# CTRL_MMR0_CFG0 register map
Vendor: Texas Instruments
Registers are 32-bit, read-write, reset 0x0 unless marked. A register's access mark holds for its fields unless they carry their own. Offsets are as the file gives them; [hi:lo] are bit positions; {n}, {i} and the like mark numbered series.

## CTRL_MMR0_CFG0 (part 7 of 9)
0xC290 CFG0_DSP0_LBIST_SIG ro — Contains expected MISR output value
  [31:0] DSP0_LBIST_SIG_MISR_SIG — MISR signature
0xC294 CFG0_DSP1_LBIST_SIG ro — Contains expected MISR output value
  [31:0] DSP1_LBIST_SIG_MISR_SIG — MISR signature
0xC2A0 CFG0_MPU0_LBIST_SIG ro — Contains expected MISR output value
  [31:0] MPU0_LBIST_SIG_MISR_SIG — MISR signature
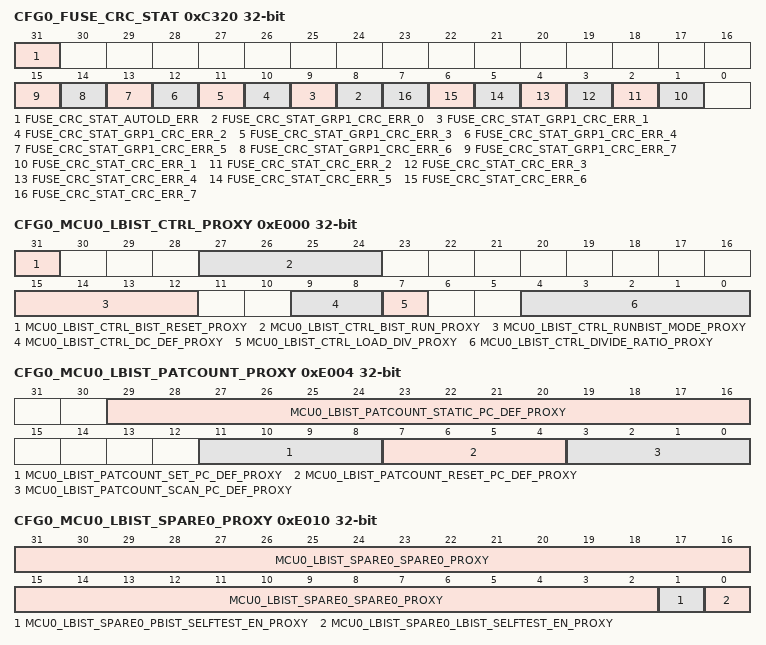
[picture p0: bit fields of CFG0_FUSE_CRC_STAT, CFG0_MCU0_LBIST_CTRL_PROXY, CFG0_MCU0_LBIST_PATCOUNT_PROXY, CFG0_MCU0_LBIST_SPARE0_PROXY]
0xC320 CFG0_FUSE_CRC_STAT ro — Indicates status of fuse chain CRC
  [31] FUSE_CRC_STAT_AUTOLD_ERR — Indicates eFuse autoload or programmation error on any chain
  [n+8] FUSE_CRC_STAT_GRP1_CRC_ERR_{n} (n=0..7) — Indicates eFuse CRC error on group1 chain {n}
  [n] FUSE_CRC_STAT_CRC_ERR_{n} (n=1..7) — Indicates eFuse CRC error on chain {n}
{0xD100+4i} CFG0_CLAIMREG_P3_R{i}_READONLY ro (i=0..13)
  [31:0] CLAIMREG_P3_R{i}_READONLY — Claim bits for Partition 3
0xE000 CFG0_MCU0_LBIST_CTRL_PROXY — Configures and enables LBIST operation
  [31] MCU0_LBIST_CTRL_BIST_RESET_PROXY — Reset LBIST macro
  [27:24] MCU0_LBIST_CTRL_BIST_RUN_PROXY — Starts LBIST if all bits are 1
  [15:12] MCU0_LBIST_CTRL_RUNBIST_MODE_PROXY — Runbist mode enable if all bits are 1
  [9:8] MCU0_LBIST_CTRL_DC_DEF_PROXY — Clock delay after scan_enable switching
  [7] MCU0_LBIST_CTRL_LOAD_DIV_PROXY — Loads LBIST clock divide ratio on transition from 0 to 1
  [4:0] MCU0_LBIST_CTRL_DIVIDE_RATIO_PROXY — LBIST clock divide ratio
0xE004 CFG0_MCU0_LBIST_PATCOUNT_PROXY — Specifies the number of LBIST patterns to run
  [29:16] MCU0_LBIST_PATCOUNT_STATIC_PC_DEF_PROXY — Number of stuck-at patterns to run
  [11:8] MCU0_LBIST_PATCOUNT_SET_PC_DEF_PROXY — Number of set patterns to run
  [7:4] MCU0_LBIST_PATCOUNT_RESET_PC_DEF_PROXY — Number of reset patterns to run
  [3:0] MCU0_LBIST_PATCOUNT_SCAN_PC_DEF_PROXY — Number of chain test patterns to run
0xE008 CFG0_MCU0_LBIST_SEED0_PROXY — Specifies the 32 LSBs of the PRPG seed
  [31:0] MCU0_LBIST_SEED0_PRPG_DEF_PROXY — Initial seed for PRPG (bits 31:0)
0xE00C CFG0_MCU0_LBIST_SEED1_PROXY — Specifies the 21 MSBs of the PRPG seed
  [20:0] MCU0_LBIST_SEED1_PRPG_DEF_PROXY — Initial seed for PRPG (bits 52:32)
0xE010 CFG0_MCU0_LBIST_SPARE0_PROXY — Spare LBIST control bits
  [31:2] MCU0_LBIST_SPARE0_SPARE0_PROXY — LBIST spare bits
  [1] MCU0_LBIST_SPARE0_PBIST_SELFTEST_EN_PROXY — PBIST isolation control
  [0] MCU0_LBIST_SPARE0_LBIST_SELFTEST_EN_PROXY — LBIST isolation control
0xE014 CFG0_MCU0_LBIST_SPARE1_PROXY — Spare LBIST control bits
  [31:0] MCU0_LBIST_SPARE1_SPARE1_PROXY — LBIST spare bits
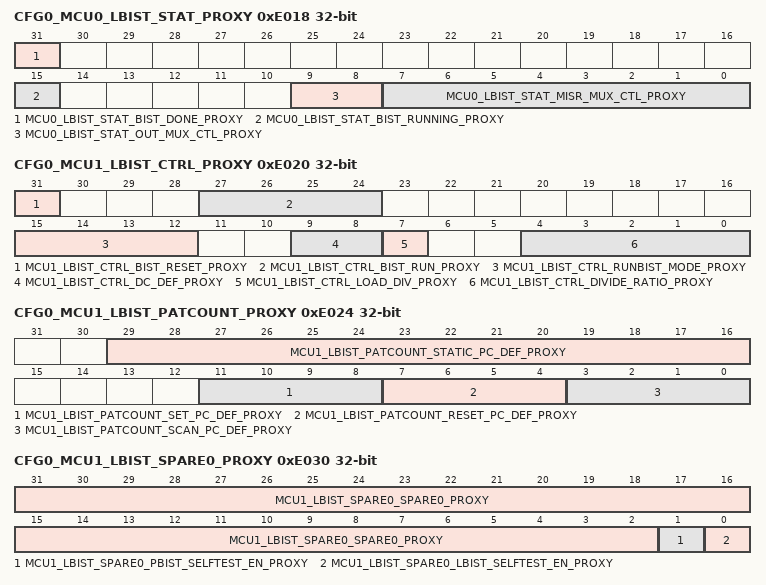
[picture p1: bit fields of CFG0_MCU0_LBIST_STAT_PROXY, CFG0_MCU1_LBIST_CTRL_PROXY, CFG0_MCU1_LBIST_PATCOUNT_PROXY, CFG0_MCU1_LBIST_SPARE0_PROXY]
0xE018 CFG0_MCU0_LBIST_STAT_PROXY access per field — Indicates LBIST status and provides MISR selection control
  [31] MCU0_LBIST_STAT_BIST_DONE_PROXY ro — LBIST is done
  [15] MCU0_LBIST_STAT_BIST_RUNNING_PROXY ro — LBIST is running
  [9:8] MCU0_LBIST_STAT_OUT_MUX_CTL_PROXY rw — Selects source of LBIST output 00 - LBIST IP PID value 01 - LBIST CTRL ID value 1x - MISR value
  [7:0] MCU0_LBIST_STAT_MISR_MUX_CTL_PROXY rw — Selects block of 32 MISR bits to read. A value of 0 selects a compacted 32-bit version of the full MISR. A value of 1-32 select a 32-bit segment of the MISR.
0xE01C CFG0_MCU0_LBIST_MISR_PROXY ro — Contains LBIST MISR output value
  [31:0] MCU0_LBIST_MISR_MISR_RESULT_PROXY — 32-bits of MISR value selected by misr_mux_ctl
0xE020 CFG0_MCU1_LBIST_CTRL_PROXY — Configures and enables LBIST operation
  [31] MCU1_LBIST_CTRL_BIST_RESET_PROXY — Reset LBIST macro
  [27:24] MCU1_LBIST_CTRL_BIST_RUN_PROXY — Starts LBIST if all bits are 1
  [15:12] MCU1_LBIST_CTRL_RUNBIST_MODE_PROXY — Runbist mode enable if all bits are 1
  [9:8] MCU1_LBIST_CTRL_DC_DEF_PROXY — Clock delay after scan_enable switching
  [7] MCU1_LBIST_CTRL_LOAD_DIV_PROXY — Loads LBIST clock divide ratio on transition from 0 to 1
  [4:0] MCU1_LBIST_CTRL_DIVIDE_RATIO_PROXY — LBIST clock divide ratio
0xE024 CFG0_MCU1_LBIST_PATCOUNT_PROXY — Specifies the number of LBIST patterns to run
  [29:16] MCU1_LBIST_PATCOUNT_STATIC_PC_DEF_PROXY — Number of stuck-at patterns to run
  [11:8] MCU1_LBIST_PATCOUNT_SET_PC_DEF_PROXY — Number of set patterns to run
  [7:4] MCU1_LBIST_PATCOUNT_RESET_PC_DEF_PROXY — Number of reset patterns to run
  [3:0] MCU1_LBIST_PATCOUNT_SCAN_PC_DEF_PROXY — Number of chain test patterns to run
0xE028 CFG0_MCU1_LBIST_SEED0_PROXY — Specifies the 32 LSBs of the PRPG seed
  [31:0] MCU1_LBIST_SEED0_PRPG_DEF_PROXY — Initial seed for PRPG (bits 31:0)
0xE02C CFG0_MCU1_LBIST_SEED1_PROXY — Specifies the 21 MSBs of the PRPG seed
  [20:0] MCU1_LBIST_SEED1_PRPG_DEF_PROXY — Initial seed for PRPG (bits 52:32)
0xE030 CFG0_MCU1_LBIST_SPARE0_PROXY — Spare LBIST control bits
  [31:2] MCU1_LBIST_SPARE0_SPARE0_PROXY — LBIST spare bits
  [1] MCU1_LBIST_SPARE0_PBIST_SELFTEST_EN_PROXY — PBIST isolation control
  [0] MCU1_LBIST_SPARE0_LBIST_SELFTEST_EN_PROXY — LBIST isolation control
0xE034 CFG0_MCU1_LBIST_SPARE1_PROXY — Spare LBIST control bits
  [31:0] MCU1_LBIST_SPARE1_SPARE1_PROXY — LBIST spare bits
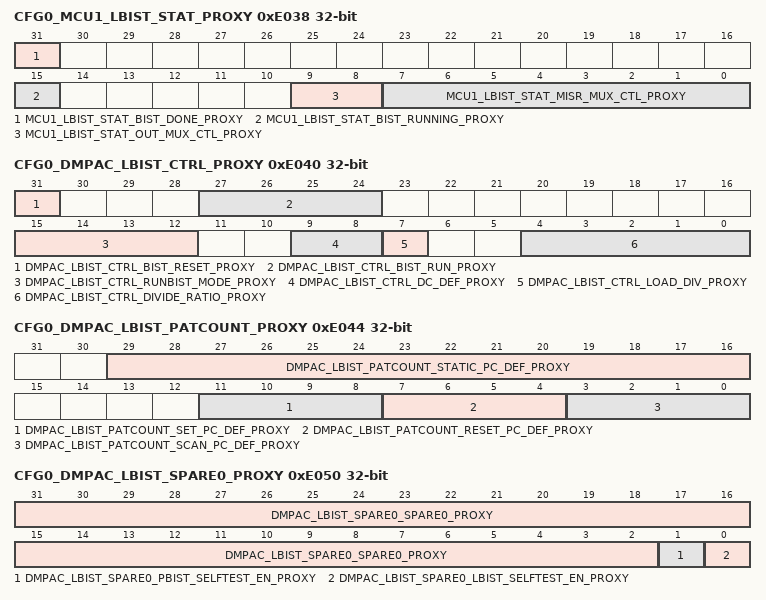
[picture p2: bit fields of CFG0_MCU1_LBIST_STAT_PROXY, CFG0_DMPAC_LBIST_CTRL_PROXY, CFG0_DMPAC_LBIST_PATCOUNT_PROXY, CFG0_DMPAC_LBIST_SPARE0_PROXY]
0xE038 CFG0_MCU1_LBIST_STAT_PROXY access per field — Indicates LBIST status and provides MISR selection control
  [31] MCU1_LBIST_STAT_BIST_DONE_PROXY ro — LBIST is done
  [15] MCU1_LBIST_STAT_BIST_RUNNING_PROXY ro — LBIST is running
  [9:8] MCU1_LBIST_STAT_OUT_MUX_CTL_PROXY rw — Selects source of LBIST output 00 - LBIST IP PID value 01 - LBIST CTRL ID value 1x - MISR value
  [7:0] MCU1_LBIST_STAT_MISR_MUX_CTL_PROXY rw — Selects block of 32 MISR bits to read. A value of 0 selects a compacted 32-bit version of the full MISR. A value of 1-32 select a 32-bit segment of the MISR.
0xE03C CFG0_MCU1_LBIST_MISR_PROXY ro — Contains LBIST MISR output value
  [31:0] MCU1_LBIST_MISR_MISR_RESULT_PROXY — 32-bits of MISR value selected by misr_mux_ctl
0xE040 CFG0_DMPAC_LBIST_CTRL_PROXY — Configures and enables LBIST operation
  [31] DMPAC_LBIST_CTRL_BIST_RESET_PROXY — Reset LBIST macro
  [27:24] DMPAC_LBIST_CTRL_BIST_RUN_PROXY — Starts LBIST if all bits are 1
  [15:12] DMPAC_LBIST_CTRL_RUNBIST_MODE_PROXY — Runbist mode enable if all bits are 1
  [9:8] DMPAC_LBIST_CTRL_DC_DEF_PROXY — Clock delay after scan_enable switching
  [7] DMPAC_LBIST_CTRL_LOAD_DIV_PROXY — Loads LBIST clock divide ratio on transition from 0 to 1
  [4:0] DMPAC_LBIST_CTRL_DIVIDE_RATIO_PROXY — LBIST clock divide ratio
0xE044 CFG0_DMPAC_LBIST_PATCOUNT_PROXY — Specifies the number of LBIST patterns to run
  [29:16] DMPAC_LBIST_PATCOUNT_STATIC_PC_DEF_PROXY — Number of stuck-at patterns to run
  [11:8] DMPAC_LBIST_PATCOUNT_SET_PC_DEF_PROXY — Number of set patterns to run
  [7:4] DMPAC_LBIST_PATCOUNT_RESET_PC_DEF_PROXY — Number of reset patterns to run
  [3:0] DMPAC_LBIST_PATCOUNT_SCAN_PC_DEF_PROXY — Number of chain test patterns to run
0xE048 CFG0_DMPAC_LBIST_SEED0_PROXY — Specifies the 32 LSBs of the PRPG seed
  [31:0] DMPAC_LBIST_SEED0_PRPG_DEF_PROXY — Initial seed for PRPG (bits 31:0)
0xE04C CFG0_DMPAC_LBIST_SEED1_PROXY — Specifies the 21 MSBs of the PRPG seed
  [20:0] DMPAC_LBIST_SEED1_PRPG_DEF_PROXY — Initial seed for PRPG (bits 52:32)
0xE050 CFG0_DMPAC_LBIST_SPARE0_PROXY — Spare LBIST control bits
  [31:2] DMPAC_LBIST_SPARE0_SPARE0_PROXY — LBIST spare bits
  [1] DMPAC_LBIST_SPARE0_PBIST_SELFTEST_EN_PROXY — PBIST isolation control
  [0] DMPAC_LBIST_SPARE0_LBIST_SELFTEST_EN_PROXY — LBIST isolation control
0xE054 CFG0_DMPAC_LBIST_SPARE1_PROXY — Spare LBIST control bits
  [31:0] DMPAC_LBIST_SPARE1_SPARE1_PROXY — LBIST spare bits
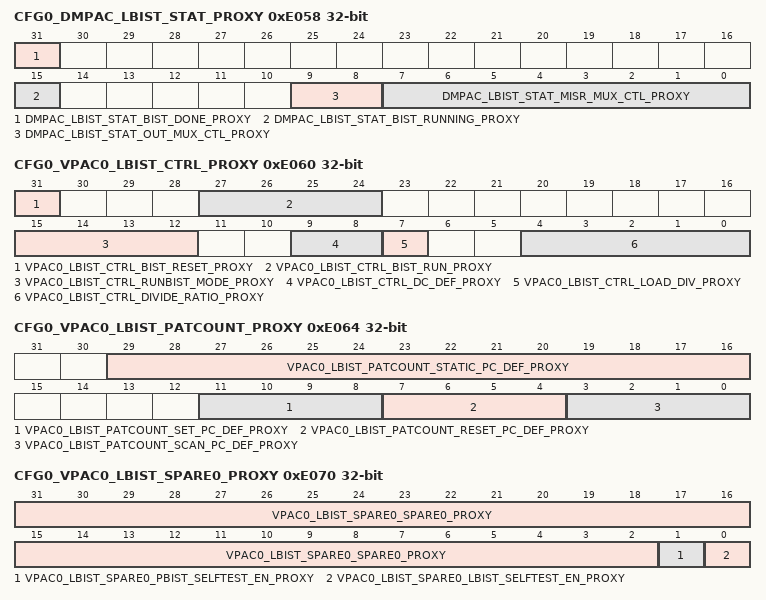
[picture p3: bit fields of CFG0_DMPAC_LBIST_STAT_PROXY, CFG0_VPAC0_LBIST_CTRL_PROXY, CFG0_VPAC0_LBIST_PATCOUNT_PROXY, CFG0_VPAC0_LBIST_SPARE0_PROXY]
0xE058 CFG0_DMPAC_LBIST_STAT_PROXY access per field — Indicates LBIST status and provides MISR selection control
  [31] DMPAC_LBIST_STAT_BIST_DONE_PROXY ro — LBIST is done
  [15] DMPAC_LBIST_STAT_BIST_RUNNING_PROXY ro — LBIST is running
  [9:8] DMPAC_LBIST_STAT_OUT_MUX_CTL_PROXY rw — Selects source of LBIST output 00 - LBIST IP PID value 01 - LBIST CTRL ID value 1x - MISR value
  [7:0] DMPAC_LBIST_STAT_MISR_MUX_CTL_PROXY rw — Selects block of 32 MISR bits to read. A value of 0 selects a compacted 32-bit version of the full MISR. A value of 1-32 select a 32-bit segment of the MISR.
0xE05C CFG0_DMPAC_LBIST_MISR_PROXY ro — Contains LBIST MISR output value
  [31:0] DMPAC_LBIST_MISR_MISR_RESULT_PROXY — 32-bits of MISR value selected by misr_mux_ctl
0xE060 CFG0_VPAC0_LBIST_CTRL_PROXY — Configures and enables LBIST operation
  [31] VPAC0_LBIST_CTRL_BIST_RESET_PROXY — Reset LBIST macro
  [27:24] VPAC0_LBIST_CTRL_BIST_RUN_PROXY — Starts LBIST if all bits are 1
  [15:12] VPAC0_LBIST_CTRL_RUNBIST_MODE_PROXY — Runbist mode enable if all bits are 1
  [9:8] VPAC0_LBIST_CTRL_DC_DEF_PROXY — Clock delay after scan_enable switching
  [7] VPAC0_LBIST_CTRL_LOAD_DIV_PROXY — Loads LBIST clock divide ratio on transition from 0 to 1
  [4:0] VPAC0_LBIST_CTRL_DIVIDE_RATIO_PROXY — LBIST clock divide ratio
0xE064 CFG0_VPAC0_LBIST_PATCOUNT_PROXY — Specifies the number of LBIST patterns to run
  [29:16] VPAC0_LBIST_PATCOUNT_STATIC_PC_DEF_PROXY — Number of stuck-at patterns to run
  [11:8] VPAC0_LBIST_PATCOUNT_SET_PC_DEF_PROXY — Number of set patterns to run
  [7:4] VPAC0_LBIST_PATCOUNT_RESET_PC_DEF_PROXY — Number of reset patterns to run
  [3:0] VPAC0_LBIST_PATCOUNT_SCAN_PC_DEF_PROXY — Number of chain test patterns to run
0xE068 CFG0_VPAC0_LBIST_SEED0_PROXY — Specifies the 32 LSBs of the PRPG seed
  [31:0] VPAC0_LBIST_SEED0_PRPG_DEF_PROXY — Initial seed for PRPG (bits 31:0)
0xE06C CFG0_VPAC0_LBIST_SEED1_PROXY — Specifies the 21 MSBs of the PRPG seed
  [20:0] VPAC0_LBIST_SEED1_PRPG_DEF_PROXY — Initial seed for PRPG (bits 52:32)
0xE070 CFG0_VPAC0_LBIST_SPARE0_PROXY — Spare LBIST control bits
  [31:2] VPAC0_LBIST_SPARE0_SPARE0_PROXY — LBIST spare bits
  [1] VPAC0_LBIST_SPARE0_PBIST_SELFTEST_EN_PROXY — PBIST isolation control
  [0] VPAC0_LBIST_SPARE0_LBIST_SELFTEST_EN_PROXY — LBIST isolation control
0xE074 CFG0_VPAC0_LBIST_SPARE1_PROXY — Spare LBIST control bits
  [31:0] VPAC0_LBIST_SPARE1_SPARE1_PROXY — LBIST spare bits
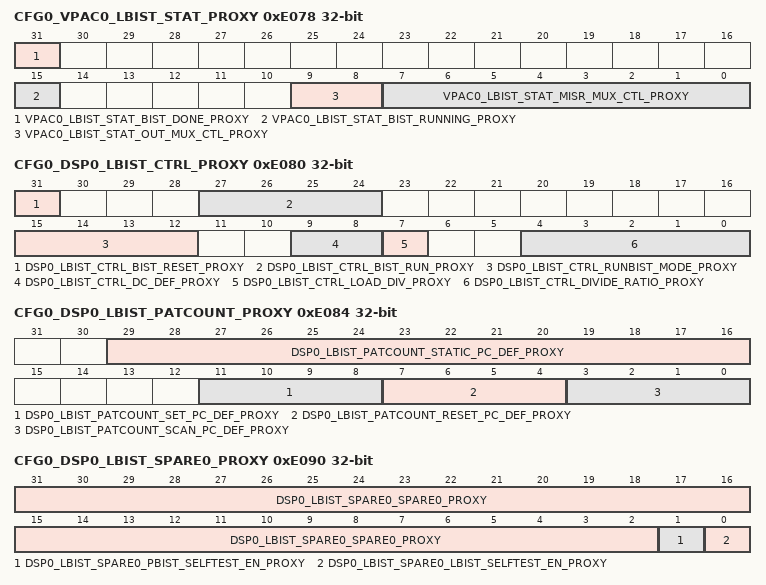
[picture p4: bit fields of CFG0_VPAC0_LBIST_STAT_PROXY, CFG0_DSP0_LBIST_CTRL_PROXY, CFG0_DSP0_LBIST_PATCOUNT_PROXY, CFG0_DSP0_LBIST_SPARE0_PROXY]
0xE078 CFG0_VPAC0_LBIST_STAT_PROXY access per field — Indicates LBIST status and provides MISR selection control
  [31] VPAC0_LBIST_STAT_BIST_DONE_PROXY ro — LBIST is done
  [15] VPAC0_LBIST_STAT_BIST_RUNNING_PROXY ro — LBIST is running
  [9:8] VPAC0_LBIST_STAT_OUT_MUX_CTL_PROXY rw — Selects source of LBIST output 00 - LBIST IP PID value 01 - LBIST CTRL ID value 1x - MISR value
  [7:0] VPAC0_LBIST_STAT_MISR_MUX_CTL_PROXY rw — Selects block of 32 MISR bits to read. A value of 0 selects a compacted 32-bit version of the full MISR. A value of 1-32 select a 32-bit segment of the MISR.
0xE07C CFG0_VPAC0_LBIST_MISR_PROXY ro — Contains LBIST MISR output value
  [31:0] VPAC0_LBIST_MISR_MISR_RESULT_PROXY — 32-bits of MISR value selected by misr_mux_ctl
0xE080 CFG0_DSP0_LBIST_CTRL_PROXY — Configures and enables LBIST operation
  [31] DSP0_LBIST_CTRL_BIST_RESET_PROXY — Reset LBIST macro
  [27:24] DSP0_LBIST_CTRL_BIST_RUN_PROXY — Starts LBIST if all bits are 1
  [15:12] DSP0_LBIST_CTRL_RUNBIST_MODE_PROXY — Runbist mode enable if all bits are 1
  [9:8] DSP0_LBIST_CTRL_DC_DEF_PROXY — Clock delay after scan_enable switching
  [7] DSP0_LBIST_CTRL_LOAD_DIV_PROXY — Loads LBIST clock divide ratio on transition from 0 to 1
  [4:0] DSP0_LBIST_CTRL_DIVIDE_RATIO_PROXY — LBIST clock divide ratio
0xE084 CFG0_DSP0_LBIST_PATCOUNT_PROXY — Specifies the number of LBIST patterns to run
  [29:16] DSP0_LBIST_PATCOUNT_STATIC_PC_DEF_PROXY — Number of stuck-at patterns to run
  [11:8] DSP0_LBIST_PATCOUNT_SET_PC_DEF_PROXY — Number of set patterns to run
  [7:4] DSP0_LBIST_PATCOUNT_RESET_PC_DEF_PROXY — Number of reset patterns to run
  [3:0] DSP0_LBIST_PATCOUNT_SCAN_PC_DEF_PROXY — Number of chain test patterns to run
0xE088 CFG0_DSP0_LBIST_SEED0_PROXY — Specifies the 32 LSBs of the PRPG seed
  [31:0] DSP0_LBIST_SEED0_PRPG_DEF_PROXY — Initial seed for PRPG (bits 31:0)
0xE08C CFG0_DSP0_LBIST_SEED1_PROXY — Specifies the 21 MSBs of the PRPG seed
  [20:0] DSP0_LBIST_SEED1_PRPG_DEF_PROXY — Initial seed for PRPG (bits 52:32)
0xE090 CFG0_DSP0_LBIST_SPARE0_PROXY — Spare LBIST control bits
  [31:2] DSP0_LBIST_SPARE0_SPARE0_PROXY — LBIST spare bits
  [1] DSP0_LBIST_SPARE0_PBIST_SELFTEST_EN_PROXY — PBIST isolation control
  [0] DSP0_LBIST_SPARE0_LBIST_SELFTEST_EN_PROXY — LBIST isolation control
0xE094 CFG0_DSP0_LBIST_SPARE1_PROXY — Spare LBIST control bits
  [31:0] DSP0_LBIST_SPARE1_SPARE1_PROXY — LBIST spare bits
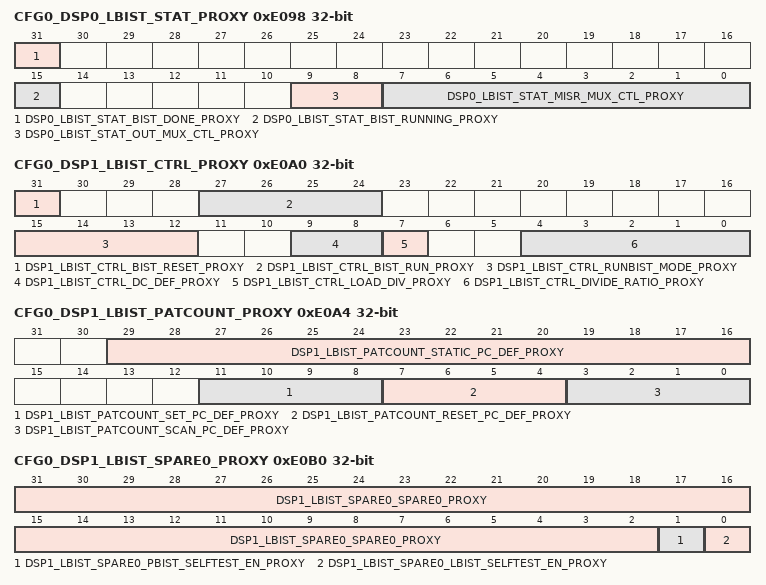
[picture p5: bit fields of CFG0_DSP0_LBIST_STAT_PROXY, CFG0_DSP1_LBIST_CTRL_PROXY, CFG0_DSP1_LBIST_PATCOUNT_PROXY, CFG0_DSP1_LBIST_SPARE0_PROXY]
0xE098 CFG0_DSP0_LBIST_STAT_PROXY access per field — Indicates LBIST status and provides MISR selection control
  [31] DSP0_LBIST_STAT_BIST_DONE_PROXY ro — LBIST is done
  [15] DSP0_LBIST_STAT_BIST_RUNNING_PROXY ro — LBIST is running
  [9:8] DSP0_LBIST_STAT_OUT_MUX_CTL_PROXY rw — Selects source of LBIST output 00 - LBIST IP PID value 01 - LBIST CTRL ID value 1x - MISR value
  [7:0] DSP0_LBIST_STAT_MISR_MUX_CTL_PROXY rw — Selects block of 32 MISR bits to read. A value of 0 selects a compacted 32-bit version of the full MISR. A value of 1-32 select a 32-bit segment of the MISR.
0xE09C CFG0_DSP0_LBIST_MISR_PROXY ro — Contains LBIST MISR output value
  [31:0] DSP0_LBIST_MISR_MISR_RESULT_PROXY — 32-bits of MISR value selected by misr_mux_ctl
0xE0A0 CFG0_DSP1_LBIST_CTRL_PROXY — Configures and enables LBIST operation
  [31] DSP1_LBIST_CTRL_BIST_RESET_PROXY — Reset LBIST macro
  [27:24] DSP1_LBIST_CTRL_BIST_RUN_PROXY — Starts LBIST if all bits are 1
  [15:12] DSP1_LBIST_CTRL_RUNBIST_MODE_PROXY — Runbist mode enable if all bits are 1
  [9:8] DSP1_LBIST_CTRL_DC_DEF_PROXY — Clock delay after scan_enable switching
  [7] DSP1_LBIST_CTRL_LOAD_DIV_PROXY — Loads LBIST clock divide ratio on transition from 0 to 1
  [4:0] DSP1_LBIST_CTRL_DIVIDE_RATIO_PROXY — LBIST clock divide ratio
0xE0A4 CFG0_DSP1_LBIST_PATCOUNT_PROXY — Specifies the number of LBIST patterns to run
  [29:16] DSP1_LBIST_PATCOUNT_STATIC_PC_DEF_PROXY — Number of stuck-at patterns to run
  [11:8] DSP1_LBIST_PATCOUNT_SET_PC_DEF_PROXY — Number of set patterns to run
  [7:4] DSP1_LBIST_PATCOUNT_RESET_PC_DEF_PROXY — Number of reset patterns to run
  [3:0] DSP1_LBIST_PATCOUNT_SCAN_PC_DEF_PROXY — Number of chain test patterns to run
0xE0A8 CFG0_DSP1_LBIST_SEED0_PROXY — Specifies the 32 LSBs of the PRPG seed
  [31:0] DSP1_LBIST_SEED0_PRPG_DEF_PROXY — Initial seed for PRPG (bits 31:0)
0xE0AC CFG0_DSP1_LBIST_SEED1_PROXY — Specifies the 21 MSBs of the PRPG seed
  [20:0] DSP1_LBIST_SEED1_PRPG_DEF_PROXY — Initial seed for PRPG (bits 52:32)
0xE0B0 CFG0_DSP1_LBIST_SPARE0_PROXY — Spare LBIST control bits
  [31:2] DSP1_LBIST_SPARE0_SPARE0_PROXY — LBIST spare bits
  [1] DSP1_LBIST_SPARE0_PBIST_SELFTEST_EN_PROXY — PBIST isolation control
  [0] DSP1_LBIST_SPARE0_LBIST_SELFTEST_EN_PROXY — LBIST isolation control
0xE0B4 CFG0_DSP1_LBIST_SPARE1_PROXY — Spare LBIST control bits
  [31:0] DSP1_LBIST_SPARE1_SPARE1_PROXY — LBIST spare bits
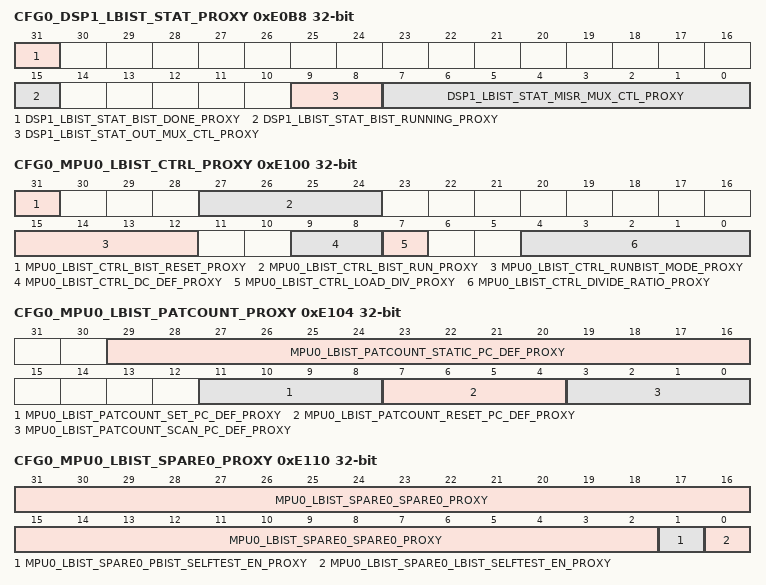
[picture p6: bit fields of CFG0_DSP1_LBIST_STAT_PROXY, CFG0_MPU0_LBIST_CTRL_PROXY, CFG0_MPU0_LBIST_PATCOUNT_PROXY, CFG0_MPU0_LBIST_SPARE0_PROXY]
0xE0B8 CFG0_DSP1_LBIST_STAT_PROXY access per field — Indicates LBIST status and provides MISR selection control
  [31] DSP1_LBIST_STAT_BIST_DONE_PROXY ro — LBIST is done
  [15] DSP1_LBIST_STAT_BIST_RUNNING_PROXY ro — LBIST is running
  [9:8] DSP1_LBIST_STAT_OUT_MUX_CTL_PROXY rw — Selects source of LBIST output 00 - LBIST IP PID value 01 - LBIST CTRL ID value 1x - MISR value
  [7:0] DSP1_LBIST_STAT_MISR_MUX_CTL_PROXY rw — Selects block of 32 MISR bits to read. A value of 0 selects a compacted 32-bit version of the full MISR. A value of 1-32 select a 32-bit segment of the MISR.
0xE0BC CFG0_DSP1_LBIST_MISR_PROXY ro — Contains LBIST MISR output value
  [31:0] DSP1_LBIST_MISR_MISR_RESULT_PROXY — 32-bits of MISR value selected by misr_mux_ctl
0xE100 CFG0_MPU0_LBIST_CTRL_PROXY — Configures and enables LBIST operation
  [31] MPU0_LBIST_CTRL_BIST_RESET_PROXY — Reset LBIST macro
  [27:24] MPU0_LBIST_CTRL_BIST_RUN_PROXY — Starts LBIST if all bits are 1
  [15:12] MPU0_LBIST_CTRL_RUNBIST_MODE_PROXY — Runbist mode enable if all bits are 1
  [9:8] MPU0_LBIST_CTRL_DC_DEF_PROXY — Clock delay after scan_enable switching
  [7] MPU0_LBIST_CTRL_LOAD_DIV_PROXY — Loads LBIST clock divide ratio on transition from 0 to 1
  [4:0] MPU0_LBIST_CTRL_DIVIDE_RATIO_PROXY — LBIST clock divide ratio
0xE104 CFG0_MPU0_LBIST_PATCOUNT_PROXY — Specifies the number of LBIST patterns to run
  [29:16] MPU0_LBIST_PATCOUNT_STATIC_PC_DEF_PROXY — Number of stuck-at patterns to run
  [11:8] MPU0_LBIST_PATCOUNT_SET_PC_DEF_PROXY — Number of set patterns to run
  [7:4] MPU0_LBIST_PATCOUNT_RESET_PC_DEF_PROXY — Number of reset patterns to run
  [3:0] MPU0_LBIST_PATCOUNT_SCAN_PC_DEF_PROXY — Number of chain test patterns to run
0xE108 CFG0_MPU0_LBIST_SEED0_PROXY — Specifies the 32 LSBs of the PRPG seed
  [31:0] MPU0_LBIST_SEED0_PRPG_DEF_PROXY — Initial seed for PRPG (bits 31:0)
0xE10C CFG0_MPU0_LBIST_SEED1_PROXY — Specifies the 21 MSBs of the PRPG seed
  [20:0] MPU0_LBIST_SEED1_PRPG_DEF_PROXY — Initial seed for PRPG (bits 52:32)
0xE110 CFG0_MPU0_LBIST_SPARE0_PROXY — Spare LBIST control bits
  [31:2] MPU0_LBIST_SPARE0_SPARE0_PROXY — LBIST spare bits
  [1] MPU0_LBIST_SPARE0_PBIST_SELFTEST_EN_PROXY — PBIST isolation control
  [0] MPU0_LBIST_SPARE0_LBIST_SELFTEST_EN_PROXY — LBIST isolation control
0xE114 CFG0_MPU0_LBIST_SPARE1_PROXY — Spare LBIST control bits
  [31:0] MPU0_LBIST_SPARE1_SPARE1_PROXY — LBIST spare bits
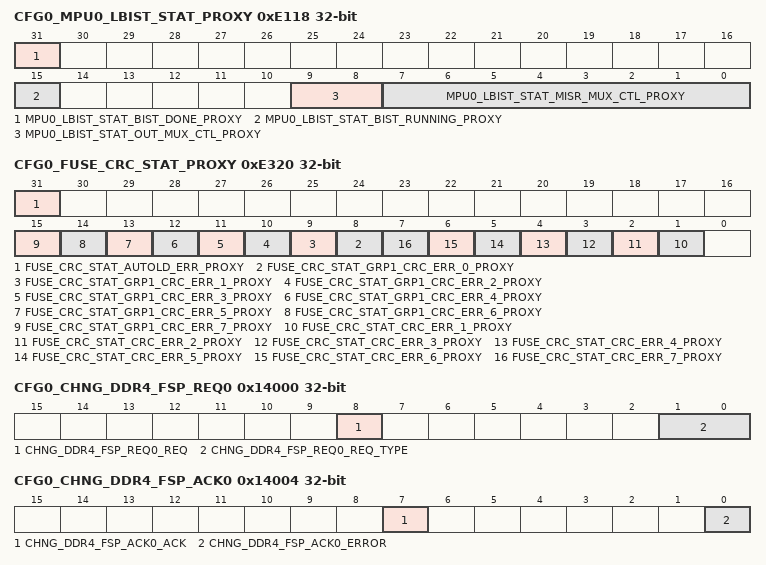
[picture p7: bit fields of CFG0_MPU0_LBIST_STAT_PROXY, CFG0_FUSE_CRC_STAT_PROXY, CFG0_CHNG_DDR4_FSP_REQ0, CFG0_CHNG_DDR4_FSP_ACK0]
0xE118 CFG0_MPU0_LBIST_STAT_PROXY access per field — Indicates LBIST status and provides MISR selection control
  [31] MPU0_LBIST_STAT_BIST_DONE_PROXY ro — LBIST is done
  [15] MPU0_LBIST_STAT_BIST_RUNNING_PROXY ro — LBIST is running
  [9:8] MPU0_LBIST_STAT_OUT_MUX_CTL_PROXY rw — Selects source of LBIST output 00 - LBIST IP PID value 01 - LBIST CTRL ID value 1x - MISR value
  [7:0] MPU0_LBIST_STAT_MISR_MUX_CTL_PROXY rw — Selects block of 32 MISR bits to read. A value of 0 selects a compacted 32-bit version of the full MISR. A value of 1-32 select a 32-bit segment of the MISR.
0xE11C CFG0_MPU0_LBIST_MISR_PROXY ro — Contains LBIST MISR output value
  [31:0] MPU0_LBIST_MISR_MISR_RESULT_PROXY — 32-bits of MISR value selected by misr_mux_ctl
0xE280 CFG0_MCU0_LBIST_SIG_PROXY ro — Contains expected MISR output value
  [31:0] MCU0_LBIST_SIG_MISR_SIG_PROXY — MISR signature
0xE284 CFG0_MCU1_LBIST_SIG_PROXY ro — Contains expected MISR output value
  [31:0] MCU1_LBIST_SIG_MISR_SIG_PROXY — MISR signature
0xE288 CFG0_DMPAC_LBIST_SIG_PROXY ro — Contains expected MISR output value
  [31:0] DMPAC_LBIST_SIG_MISR_SIG_PROXY — MISR signature
0xE28C CFG0_VPAC0_LBIST_SIG_PROXY ro — Contains expected MISR output value
  [31:0] VPAC0_LBIST_SIG_MISR_SIG_PROXY — MISR signature
0xE290 CFG0_DSP0_LBIST_SIG_PROXY ro — Contains expected MISR output value
  [31:0] DSP0_LBIST_SIG_MISR_SIG_PROXY — MISR signature
0xE294 CFG0_DSP1_LBIST_SIG_PROXY ro — Contains expected MISR output value
  [31:0] DSP1_LBIST_SIG_MISR_SIG_PROXY — MISR signature
0xE2A0 CFG0_MPU0_LBIST_SIG_PROXY ro — Contains expected MISR output value
  [31:0] MPU0_LBIST_SIG_MISR_SIG_PROXY — MISR signature
0xE320 CFG0_FUSE_CRC_STAT_PROXY ro — Indicates status of fuse chain CRC
  [31] FUSE_CRC_STAT_AUTOLD_ERR_PROXY — Indicates eFuse autoload or programmation error on any chain
  [n+8] FUSE_CRC_STAT_GRP1_CRC_ERR_{n}_PROXY (n=0..7) — Indicates eFuse CRC error on group1 chain {n}
  [n] FUSE_CRC_STAT_CRC_ERR_{n}_PROXY (n=1..7) — Indicates eFuse CRC error on chain {n}
{0xF100+4i} CFG0_CLAIMREG_P3_R{i} (i=0..13)
  [31:0] CLAIMREG_P3_R{i} — Claim bits for Partition 3
{0x10000+4i} CFG0_DV_REG{i} (i=0..7) — Register for general purpose DV use.
  [31:0] DV_REG{i}_BIT — Defined by DV usage
{0x10200+4i} CFG0_DV_REG{i}_SET access not given (i=0..3) — Set register for DV use
  [31:0] DV_REG{i}_SET_BIT — Defined by DV usage (access R/W1TS)
{0x10300+4i} CFG0_DV_REG{i}_CLR access not given (i=0..3) — Clear register for DV use
  [31:0] DV_REG{i}_CLR_BIT — Defined by DV usage (access R/W1TC)
0x10500 CFG0_AVS_CORE_MRGN_MODE0 — Controls AVS domain memory margin for DFT
  [11:0] AVS_CORE_MRGN_MODE0_HS2PARF_MEM_MRGN_ASST — DFT memory margin control Bits 0-3 - dft_mem_margin Bits 4-5 - dft_mem_ra Bits 6-8 - dft_mem_wa Bits 9-11 - dft_wpulse
0x10504 CFG0_AVS_CORE_MRGN_MODE1 — Controls AVS domain memory margin for DFT
  [11:0] AVS_CORE_MRGN_MODE1_HDDP_MEM_MRGN_ASST — DFT memory margin control Bits 0-3 - dft_mem_margin Bits 4-5 - dft_mem_ra Bits 6-8 - dft_mem_wa Bits 9-11 - dft_wpulse
0x10508 CFG0_AVS_CORE_MRGN_MODE2 — Controls AVS domain memory margin for DFT
  [11:0] AVS_CORE_MRGN_MODE2_EHDSP_MEM_MRGN_ASST — DFT memory margin control Bits 0-3 - dft_mem_margin Bits 4-5 - dft_mem_ra Bits 6-8 - dft_mem_wa Bits 9-11 - dft_wpulse
0x1050C CFG0_AVS_CORE_MRGN_MODE3 — Controls AVS domain memory margin for DFT
  [11:0] AVS_CORE_MRGN_MODE3_HD2PRF_MEM_MRGN_ASST — DFT memory margin control Bits 0-3 - dft_mem_margin Bits 4-5 - dft_mem_ra Bits 6-8 - dft_mem_wa Bits 9-11 - dft_wpulse
0x10510 CFG0_AVS_CORE_MRGN_MODE4 — Controls AVS domain memory margin for DFT
  [11:0] AVS_CORE_MRGN_MODE4_UHD2PRF_MEM_MRGN_ASST — DFT memory margin control Bits 0-3 - dft_mem_margin Bits 4-5 - dft_mem_ra Bits 6-8 - dft_mem_wa Bits 9-11 - dft_wpulse
0x10514 CFG0_AVS_CORE_MRGN_MODE5 — Controls AVS domain memory margin for DFT
  [11:0] AVS_CORE_MRGN_MODE5_ROM_MEM_MRGN_ASST — DFT memory margin control Bits 0-3 - dft_mem_margin Bits 4-5 - dft_mem_ra Bits 6-8 - dft_mem_wa Bits 9-11 - dft_wpulse
0x10518 CFG0_AVS_CORE_MRGN_MODE6 — Controls AVS domain memory margin for DFT
  [11:0] AVS_CORE_MRGN_MODE6_HDSP_MEM_MRGN_ASST — DFT memory margin control Bits 0-3 - dft_mem_margin Bits 4-5 - dft_mem_ra Bits 6-8 - dft_mem_wa Bits 9-11 - dft_wpulse
0x1051C CFG0_AVS_CORE_MRGN_MODE7 — Controls AVS domain memory margin for DFT
  [11:0] AVS_CORE_MRGN_MODE7_HSSP_MEM_MRGN_ASST — DFT memory margin control Bits 0-3 - dft_mem_margin Bits 4-5 - dft_mem_ra Bits 6-8 - dft_mem_wa Bits 9-11 - dft_wpulse
0x10520 CFG0_AVS_CORE_MRGN_MODE8 — Controls AVS domain memory margin for DFT
  [11:0] AVS_CORE_MRGN_MODE8_HD1PRF_MEM_MRGN_ASST — DFT memory margin control Bits 0-3 - dft_mem_margin Bits 4-5 - dft_mem_ra Bits 6-8 - dft_mem_wa Bits 9-11 - dft_wpulse
0x10524 CFG0_AVS_CORE_MRGN_MODE9 — Controls AVS domain memory margin for DFT
  [11:0] AVS_CORE_MRGN_MODE9_HS1PRF_MEM_MRGN_ASST — DFT memory margin control Bits 0-3 - dft_mem_margin Bits 4-5 - dft_mem_ra Bits 6-8 - dft_mem_wa Bits 9-11 - dft_wpulse
0x10540 CFG0_NON_AVS_MRGN_MODE0 — Controls non-AVS domain memory margin for DFT
  [11:0] NON_AVS_MRGN_MODE0_HS2PARF_MEM_MRGN_ASST — DFT memory margin control Bits 0-3 - dft_mem_margin Bits 4-5 - dft_mem_ra Bits 6-8 - dft_mem_wa Bits 9-11 - dft_wpulse
0x10544 CFG0_NON_AVS_MRGN_MODE1 — Controls non-AVS domain memory margin for DFT
  [11:0] NON_AVS_MRGN_MODE1_HDDP_MEM_MRGN_ASST — DFT memory margin control Bits 0-3 - dft_mem_margin Bits 4-5 - dft_mem_ra Bits 6-8 - dft_mem_wa Bits 9-11 - dft_wpulse
0x10548 CFG0_NON_AVS_MRGN_MODE2 — Controls non-AVS domain memory margin for DFT
  [11:0] NON_AVS_MRGN_MODE2_EHDSP_MEM_MRGN_ASST — DFT memory margin control Bits 0-3 - dft_mem_margin Bits 4-5 - dft_mem_ra Bits 6-8 - dft_mem_wa Bits 9-11 - dft_wpulse
0x1054C CFG0_NON_AVS_MRGN_MODE3 — Controls non-AVS domain memory margin for DFT
  [11:0] NON_AVS_MRGN_MODE3_HD2PRF_MEM_MRGN_ASST — DFT memory margin control Bits 0-3 - dft_mem_margin Bits 4-5 - dft_mem_ra Bits 6-8 - dft_mem_wa Bits 9-11 - dft_wpulse
0x10550 CFG0_NON_AVS_MRGN_MODE4 — Controls non-AVS domain memory margin for DFT
  [11:0] NON_AVS_MRGN_MODE4_UHD2PRF_MEM_MRGN_ASST — DFT memory margin control Bits 0-3 - dft_mem_margin Bits 4-5 - dft_mem_ra Bits 6-8 - dft_mem_wa Bits 9-11 - dft_wpulse
0x10554 CFG0_NON_AVS_MRGN_MODE5 — Controls non-AVS domain memory margin for DFT
  [11:0] NON_AVS_MRGN_MODE5_ROM_MEM_MRGN_ASST — DFT memory margin control Bits 0-3 - dft_mem_margin Bits 4-5 - dft_mem_ra Bits 6-8 - dft_mem_wa Bits 9-11 - dft_wpulse
0x10558 CFG0_NON_AVS_MRGN_MODE6 — Controls non-AVS domain memory margin for DFT
  [11:0] NON_AVS_MRGN_MODE6_HDSP_MEM_MRGN_ASST — DFT memory margin control Bits 0-3 - dft_mem_margin Bits 4-5 - dft_mem_ra Bits 6-8 - dft_mem_wa Bits 9-11 - dft_wpulse
0x1055C CFG0_NON_AVS_MRGN_MODE7 — Controls non-AVS domain memory margin for DFT
  [11:0] NON_AVS_MRGN_MODE7_HSSP_MEM_MRGN_ASST — DFT memory margin control Bits 0-3 - dft_mem_margin Bits 4-5 - dft_mem_ra Bits 6-8 - dft_mem_wa Bits 9-11 - dft_wpulse
0x10560 CFG0_NON_AVS_MRGN_MODE8 — Controls non-AVS domain memory margin for DFT
  [11:0] NON_AVS_MRGN_MODE8_HD1PRF_MEM_MRGN_ASST — DFT memory margin control Bits 0-3 - dft_mem_margin Bits 4-5 - dft_mem_ra Bits 6-8 - dft_mem_wa Bits 9-11 - dft_wpulse
0x10564 CFG0_NON_AVS_MRGN_MODE9 — Controls non-AVS domain memory margin for DFT
  [11:0] NON_AVS_MRGN_MODE9_HS1PRF_MEM_MRGN_ASST — DFT memory margin control Bits 0-3 - dft_mem_margin Bits 4-5 - dft_mem_ra Bits 6-8 - dft_mem_wa Bits 9-11 - dft_wpulse
0x10580 CFG0_FAST_MRGN_MODE0 — Controls fast memory margin for DFT
  [11:0] FAST_MRGN_MODE0_HS2PARF_MEM_MRGN_ASST — DFT memory margin control Bits 0-3 - dft_mem_margin Bits 4-5 - dft_mem_ra Bits 6-8 - dft_mem_wa Bits 9-11 - dft_wpulse
0x10584 CFG0_FAST_MRGN_MODE1 — Controls fast memory margin for DFT
  [11:0] FAST_MRGN_MODE1_HDDP_MEM_MRGN_ASST — DFT memory margin control Bits 0-3 - dft_mem_margin Bits 4-5 - dft_mem_ra Bits 6-8 - dft_mem_wa Bits 9-11 - dft_wpulse
0x10588 CFG0_FAST_MRGN_MODE2 — Controls fast memory margin for DFT
  [11:0] FAST_MRGN_MODE2_EHDSP_MEM_MRGN_ASST — DFT memory margin control Bits 0-3 - dft_mem_margin Bits 4-5 - dft_mem_ra Bits 6-8 - dft_mem_wa Bits 9-11 - dft_wpulse
0x1058C CFG0_FAST_MRGN_MODE3 — Controls fast memory margin for DFT
  [11:0] FAST_MRGN_MODE3_HD2PRF_MEM_MRGN_ASST — DFT memory margin control Bits 0-3 - dft_mem_margin Bits 4-5 - dft_mem_ra Bits 6-8 - dft_mem_wa Bits 9-11 - dft_wpulse
0x10590 CFG0_FAST_MRGN_MODE4 — Controls fast memory margin for DFT
  [11:0] FAST_MRGN_MODE4_UHD2PRF_MEM_MRGN_ASST — DFT memory margin control Bits 0-3 - dft_mem_margin Bits 4-5 - dft_mem_ra Bits 6-8 - dft_mem_wa Bits 9-11 - dft_wpulse
0x10594 CFG0_FAST_MRGN_MODE5 — Controls fast memory margin for DFT
  [11:0] FAST_MRGN_MODE5_ROM_MEM_MRGN_ASST — DFT memory margin control Bits 0-3 - dft_mem_margin Bits 4-5 - dft_mem_ra Bits 6-8 - dft_mem_wa Bits 9-11 - dft_wpulse
0x10598 CFG0_FAST_MRGN_MODE6 — Controls fast memory margin for DFT
  [11:0] FAST_MRGN_MODE6_HDSP_MEM_MRGN_ASST — DFT memory margin control Bits 0-3 - dft_mem_margin Bits 4-5 - dft_mem_ra Bits 6-8 - dft_mem_wa Bits 9-11 - dft_wpulse
0x1059C CFG0_FAST_MRGN_MODE7 — Controls fast memory margin for DFT
  [11:0] FAST_MRGN_MODE7_HSSP_MEM_MRGN_ASST — DFT memory margin control Bits 0-3 - dft_mem_margin Bits 4-5 - dft_mem_ra Bits 6-8 - dft_mem_wa Bits 9-11 - dft_wpulse
0x105A0 CFG0_FAST_MRGN_MODE8 — Controls fast memory margin for DFT
  [11:0] FAST_MRGN_MODE8_HD1PRF_MEM_MRGN_ASST — DFT memory margin control Bits 0-3 - dft_mem_margin Bits 4-5 - dft_mem_ra Bits 6-8 - dft_mem_wa Bits 9-11 - dft_wpulse
0x105A4 CFG0_FAST_MRGN_MODE9 — Controls fast memory margin for DFT
  [11:0] FAST_MRGN_MODE9_HS1PRF_MEM_MRGN_ASST — DFT memory margin control Bits 0-3 - dft_mem_margin Bits 4-5 - dft_mem_ra Bits 6-8 - dft_mem_wa Bits 9-11 - dft_wpulse
{0x11100+4i} CFG0_CLAIMREG_P4_R{i}_READONLY ro (i=0..11)
  [31:0] CLAIMREG_P4_R{i}_READONLY — Claim bits for Partition 4
{0x12000+4i} CFG0_DV_REG{i}_PROXY (i=0..7) — Register for general purpose DV use.
  [31:0] DV_REG{i}_BIT_PROXY — Defined by DV usage
{0x12200+4i} CFG0_DV_REG{i}_SET_PROXY access not given (i=0..3) — Set register for DV use
  [31:0] DV_REG{i}_SET_BIT_PROXY — Defined by DV usage (access R/W1TS)
{0x12300+4i} CFG0_DV_REG{i}_CLR_PROXY access not given (i=0..3) — Clear register for DV use
  [31:0] DV_REG{i}_CLR_BIT_PROXY — Defined by DV usage (access R/W1TC)
0x12500 CFG0_AVS_CORE_MRGN_MODE0_PROXY — Controls AVS domain memory margin for DFT
  [11:0] AVS_CORE_MRGN_MODE0_HS2PARF_MEM_MRGN_ASST_PROXY — DFT memory margin control Bits 0-3 - dft_mem_margin Bits 4-5 - dft_mem_ra Bits 6-8 - dft_mem_wa Bits 9-11 - dft_wpulse
0x12504 CFG0_AVS_CORE_MRGN_MODE1_PROXY — Controls AVS domain memory margin for DFT
  [11:0] AVS_CORE_MRGN_MODE1_HDDP_MEM_MRGN_ASST_PROXY — DFT memory margin control Bits 0-3 - dft_mem_margin Bits 4-5 - dft_mem_ra Bits 6-8 - dft_mem_wa Bits 9-11 - dft_wpulse
0x12508 CFG0_AVS_CORE_MRGN_MODE2_PROXY — Controls AVS domain memory margin for DFT
  [11:0] AVS_CORE_MRGN_MODE2_EHDSP_MEM_MRGN_ASST_PROXY — DFT memory margin control Bits 0-3 - dft_mem_margin Bits 4-5 - dft_mem_ra Bits 6-8 - dft_mem_wa Bits 9-11 - dft_wpulse
0x1250C CFG0_AVS_CORE_MRGN_MODE3_PROXY — Controls AVS domain memory margin for DFT
  [11:0] AVS_CORE_MRGN_MODE3_HD2PRF_MEM_MRGN_ASST_PROXY — DFT memory margin control Bits 0-3 - dft_mem_margin Bits 4-5 - dft_mem_ra Bits 6-8 - dft_mem_wa Bits 9-11 - dft_wpulse
0x12510 CFG0_AVS_CORE_MRGN_MODE4_PROXY — Controls AVS domain memory margin for DFT
  [11:0] AVS_CORE_MRGN_MODE4_UHD2PRF_MEM_MRGN_ASST_PROXY — DFT memory margin control Bits 0-3 - dft_mem_margin Bits 4-5 - dft_mem_ra Bits 6-8 - dft_mem_wa Bits 9-11 - dft_wpulse
0x12514 CFG0_AVS_CORE_MRGN_MODE5_PROXY — Controls AVS domain memory margin for DFT
  [11:0] AVS_CORE_MRGN_MODE5_ROM_MEM_MRGN_ASST_PROXY — DFT memory margin control Bits 0-3 - dft_mem_margin Bits 4-5 - dft_mem_ra Bits 6-8 - dft_mem_wa Bits 9-11 - dft_wpulse
0x12518 CFG0_AVS_CORE_MRGN_MODE6_PROXY — Controls AVS domain memory margin for DFT
  [11:0] AVS_CORE_MRGN_MODE6_HDSP_MEM_MRGN_ASST_PROXY — DFT memory margin control Bits 0-3 - dft_mem_margin Bits 4-5 - dft_mem_ra Bits 6-8 - dft_mem_wa Bits 9-11 - dft_wpulse
0x1251C CFG0_AVS_CORE_MRGN_MODE7_PROXY — Controls AVS domain memory margin for DFT
  [11:0] AVS_CORE_MRGN_MODE7_HSSP_MEM_MRGN_ASST_PROXY — DFT memory margin control Bits 0-3 - dft_mem_margin Bits 4-5 - dft_mem_ra Bits 6-8 - dft_mem_wa Bits 9-11 - dft_wpulse
0x12520 CFG0_AVS_CORE_MRGN_MODE8_PROXY — Controls AVS domain memory margin for DFT
  [11:0] AVS_CORE_MRGN_MODE8_HD1PRF_MEM_MRGN_ASST_PROXY — DFT memory margin control Bits 0-3 - dft_mem_margin Bits 4-5 - dft_mem_ra Bits 6-8 - dft_mem_wa Bits 9-11 - dft_wpulse
0x12524 CFG0_AVS_CORE_MRGN_MODE9_PROXY — Controls AVS domain memory margin for DFT
  [11:0] AVS_CORE_MRGN_MODE9_HS1PRF_MEM_MRGN_ASST_PROXY — DFT memory margin control Bits 0-3 - dft_mem_margin Bits 4-5 - dft_mem_ra Bits 6-8 - dft_mem_wa Bits 9-11 - dft_wpulse
0x12540 CFG0_NON_AVS_MRGN_MODE0_PROXY — Controls non-AVS domain memory margin for DFT
  [11:0] NON_AVS_MRGN_MODE0_HS2PARF_MEM_MRGN_ASST_PROXY — DFT memory margin control Bits 0-3 - dft_mem_margin Bits 4-5 - dft_mem_ra Bits 6-8 - dft_mem_wa Bits 9-11 - dft_wpulse
0x12544 CFG0_NON_AVS_MRGN_MODE1_PROXY — Controls non-AVS domain memory margin for DFT
  [11:0] NON_AVS_MRGN_MODE1_HDDP_MEM_MRGN_ASST_PROXY — DFT memory margin control Bits 0-3 - dft_mem_margin Bits 4-5 - dft_mem_ra Bits 6-8 - dft_mem_wa Bits 9-11 - dft_wpulse
0x12548 CFG0_NON_AVS_MRGN_MODE2_PROXY — Controls non-AVS domain memory margin for DFT
  [11:0] NON_AVS_MRGN_MODE2_EHDSP_MEM_MRGN_ASST_PROXY — DFT memory margin control Bits 0-3 - dft_mem_margin Bits 4-5 - dft_mem_ra Bits 6-8 - dft_mem_wa Bits 9-11 - dft_wpulse
0x1254C CFG0_NON_AVS_MRGN_MODE3_PROXY — Controls non-AVS domain memory margin for DFT
  [11:0] NON_AVS_MRGN_MODE3_HD2PRF_MEM_MRGN_ASST_PROXY — DFT memory margin control Bits 0-3 - dft_mem_margin Bits 4-5 - dft_mem_ra Bits 6-8 - dft_mem_wa Bits 9-11 - dft_wpulse
0x12550 CFG0_NON_AVS_MRGN_MODE4_PROXY — Controls non-AVS domain memory margin for DFT
  [11:0] NON_AVS_MRGN_MODE4_UHD2PRF_MEM_MRGN_ASST_PROXY — DFT memory margin control Bits 0-3 - dft_mem_margin Bits 4-5 - dft_mem_ra Bits 6-8 - dft_mem_wa Bits 9-11 - dft_wpulse
0x12554 CFG0_NON_AVS_MRGN_MODE5_PROXY — Controls non-AVS domain memory margin for DFT
  [11:0] NON_AVS_MRGN_MODE5_ROM_MEM_MRGN_ASST_PROXY — DFT memory margin control Bits 0-3 - dft_mem_margin Bits 4-5 - dft_mem_ra Bits 6-8 - dft_mem_wa Bits 9-11 - dft_wpulse
0x12558 CFG0_NON_AVS_MRGN_MODE6_PROXY — Controls non-AVS domain memory margin for DFT
  [11:0] NON_AVS_MRGN_MODE6_HDSP_MEM_MRGN_ASST_PROXY — DFT memory margin control Bits 0-3 - dft_mem_margin Bits 4-5 - dft_mem_ra Bits 6-8 - dft_mem_wa Bits 9-11 - dft_wpulse
0x1255C CFG0_NON_AVS_MRGN_MODE7_PROXY — Controls non-AVS domain memory margin for DFT
  [11:0] NON_AVS_MRGN_MODE7_HSSP_MEM_MRGN_ASST_PROXY — DFT memory margin control Bits 0-3 - dft_mem_margin Bits 4-5 - dft_mem_ra Bits 6-8 - dft_mem_wa Bits 9-11 - dft_wpulse
0x12560 CFG0_NON_AVS_MRGN_MODE8_PROXY — Controls non-AVS domain memory margin for DFT
  [11:0] NON_AVS_MRGN_MODE8_HD1PRF_MEM_MRGN_ASST_PROXY — DFT memory margin control Bits 0-3 - dft_mem_margin Bits 4-5 - dft_mem_ra Bits 6-8 - dft_mem_wa Bits 9-11 - dft_wpulse
0x12564 CFG0_NON_AVS_MRGN_MODE9_PROXY — Controls non-AVS domain memory margin for DFT
  [11:0] NON_AVS_MRGN_MODE9_HS1PRF_MEM_MRGN_ASST_PROXY — DFT memory margin control Bits 0-3 - dft_mem_margin Bits 4-5 - dft_mem_ra Bits 6-8 - dft_mem_wa Bits 9-11 - dft_wpulse
0x12580 CFG0_FAST_MRGN_MODE0_PROXY — Controls fast memory margin for DFT
  [11:0] FAST_MRGN_MODE0_HS2PARF_MEM_MRGN_ASST_PROXY — DFT memory margin control Bits 0-3 - dft_mem_margin Bits 4-5 - dft_mem_ra Bits 6-8 - dft_mem_wa Bits 9-11 - dft_wpulse
0x12584 CFG0_FAST_MRGN_MODE1_PROXY — Controls fast memory margin for DFT
  [11:0] FAST_MRGN_MODE1_HDDP_MEM_MRGN_ASST_PROXY — DFT memory margin control Bits 0-3 - dft_mem_margin Bits 4-5 - dft_mem_ra Bits 6-8 - dft_mem_wa Bits 9-11 - dft_wpulse
0x12588 CFG0_FAST_MRGN_MODE2_PROXY — Controls fast memory margin for DFT
  [11:0] FAST_MRGN_MODE2_EHDSP_MEM_MRGN_ASST_PROXY — DFT memory margin control Bits 0-3 - dft_mem_margin Bits 4-5 - dft_mem_ra Bits 6-8 - dft_mem_wa Bits 9-11 - dft_wpulse
0x1258C CFG0_FAST_MRGN_MODE3_PROXY — Controls fast memory margin for DFT
  [11:0] FAST_MRGN_MODE3_HD2PRF_MEM_MRGN_ASST_PROXY — DFT memory margin control Bits 0-3 - dft_mem_margin Bits 4-5 - dft_mem_ra Bits 6-8 - dft_mem_wa Bits 9-11 - dft_wpulse
0x12590 CFG0_FAST_MRGN_MODE4_PROXY — Controls fast memory margin for DFT
  [11:0] FAST_MRGN_MODE4_UHD2PRF_MEM_MRGN_ASST_PROXY — DFT memory margin control Bits 0-3 - dft_mem_margin Bits 4-5 - dft_mem_ra Bits 6-8 - dft_mem_wa Bits 9-11 - dft_wpulse
0x12594 CFG0_FAST_MRGN_MODE5_PROXY — Controls fast memory margin for DFT
  [11:0] FAST_MRGN_MODE5_ROM_MEM_MRGN_ASST_PROXY — DFT memory margin control Bits 0-3 - dft_mem_margin Bits 4-5 - dft_mem_ra Bits 6-8 - dft_mem_wa Bits 9-11 - dft_wpulse
0x12598 CFG0_FAST_MRGN_MODE6_PROXY — Controls fast memory margin for DFT
  [11:0] FAST_MRGN_MODE6_HDSP_MEM_MRGN_ASST_PROXY — DFT memory margin control Bits 0-3 - dft_mem_margin Bits 4-5 - dft_mem_ra Bits 6-8 - dft_mem_wa Bits 9-11 - dft_wpulse
0x1259C CFG0_FAST_MRGN_MODE7_PROXY — Controls fast memory margin for DFT
  [11:0] FAST_MRGN_MODE7_HSSP_MEM_MRGN_ASST_PROXY — DFT memory margin control Bits 0-3 - dft_mem_margin Bits 4-5 - dft_mem_ra Bits 6-8 - dft_mem_wa Bits 9-11 - dft_wpulse
0x125A0 CFG0_FAST_MRGN_MODE8_PROXY — Controls fast memory margin for DFT
  [11:0] FAST_MRGN_MODE8_HD1PRF_MEM_MRGN_ASST_PROXY — DFT memory margin control Bits 0-3 - dft_mem_margin Bits 4-5 - dft_mem_ra Bits 6-8 - dft_mem_wa Bits 9-11 - dft_wpulse
0x125A4 CFG0_FAST_MRGN_MODE9_PROXY — Controls fast memory margin for DFT
  [11:0] FAST_MRGN_MODE9_HS1PRF_MEM_MRGN_ASST_PROXY — DFT memory margin control Bits 0-3 - dft_mem_margin Bits 4-5 - dft_mem_ra Bits 6-8 - dft_mem_wa Bits 9-11 - dft_wpulse
{0x13100+4i} CFG0_CLAIMREG_P4_R{i} (i=0..11)
  [31:0] CLAIMREG_P4_R{i} — Claim bits for Partition 4
0x14000 CFG0_CHNG_DDR4_FSP_REQ0 — This register is used to initiate a LPDDR4 frequency set point change to the DDR 0 Controller
  [8] CHNG_DDR4_FSP_REQ0_REQ — Initiate FSP frequency change
  [1:0] CHNG_DDR4_FSP_REQ0_REQ_TYPE — Frequency request typeIndicates which DDR4 frequency set point to change to
0x14004 CFG0_CHNG_DDR4_FSP_ACK0 ro — This register is used by the DDR 0 Controller to acknowledge the LPDDR4 frequency set point change request
  [7] CHNG_DDR4_FSP_ACK0_ACK — Frequency change acknowledge.This bit is only valid when CHNG_DDR4_FSP_REQ_req = 1Indication from the DDR Controller that the FSP change operation is complete 0 - FSP change operation in progress 1 - FSP change operation complete
  [0] CHNG_DDR4_FSP_ACK0_ERROR — Frequency change errorThis bit is only valid when CHNG_DDR4_FSP_REQ_req = 1 0 - FSP change was successful 1 - FSP change was not successful
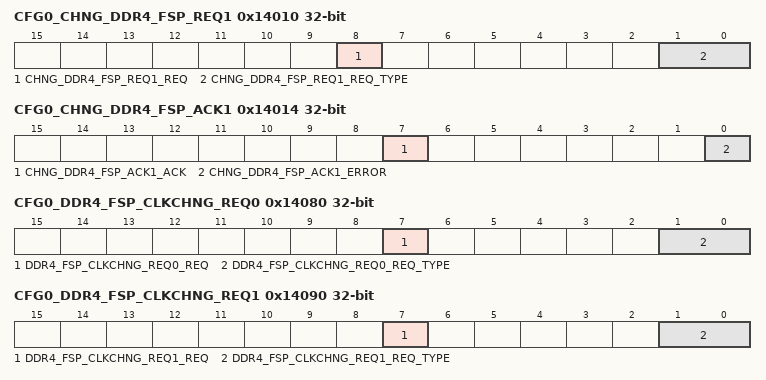
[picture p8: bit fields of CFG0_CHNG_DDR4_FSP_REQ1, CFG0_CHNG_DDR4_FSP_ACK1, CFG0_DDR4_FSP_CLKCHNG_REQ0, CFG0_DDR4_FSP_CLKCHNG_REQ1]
0x14010 CFG0_CHNG_DDR4_FSP_REQ1 — This register is used to initiate a LPDDR4 frequency set point change to the DDR 1 Controller
  [8] CHNG_DDR4_FSP_REQ1_REQ — Initiate FSP frequency change
  [1:0] CHNG_DDR4_FSP_REQ1_REQ_TYPE — Frequency request typeIndicates which DDR4 frequency set point to change to
0x14014 CFG0_CHNG_DDR4_FSP_ACK1 ro — This register is used by the DDR 1 Controller to acknowledge the LPDDR4 frequency set point change request
  [7] CHNG_DDR4_FSP_ACK1_ACK — Frequency change acknowledge.This bit is only valid when CHNG_DDR4_FSP_REQ_req = 1Indication from the DDR Controller that the FSP change operation is complete 0 - FSP change operation in progress 1 - FSP change operation complete
  [0] CHNG_DDR4_FSP_ACK1_ERROR — Frequency change errorThis bit is only valid when CHNG_DDR4_FSP_REQ_req = 1 0 - FSP change was successful 1 - FSP change was not successful
0x14080 CFG0_DDR4_FSP_CLKCHNG_REQ0 ro — This register is used by the DDR 0 Controller to request the DDR0 PLL clock frequency change. This can occur as part of DDR4 initialization and training or in response to a LPDDR4 FSP change request.
  [7] DDR4_FSP_CLKCHNG_REQ0_REQ — DDR Controller FSP clock change requestIndicates that the DDR controller needs the DDR clock changed to the frequency indicated by the req_type field. This bit is cleared when the DDR4_FSP_CLKCHNG_ACK_ack bit is set.
  [1:0] DDR4_FSP_CLKCHNG_REQ0_REQ_TYPE — Frequency request typeIndicates which DDR4 FSP frequency to which the DDR Controller wants the DDR clock set
0x14090 CFG0_DDR4_FSP_CLKCHNG_REQ1 ro — This register is used by the DDR 1 Controller to request the DDR1 PLL clock frequency change. This can occur as part of DDR4 initialization and training or in response to a LPDDR4 FSP change request.
  [7] DDR4_FSP_CLKCHNG_REQ1_REQ — DDR Controller FSP clock change requestIndicates that the DDR controller needs the DDR clock changed to the frequency indicated by the req_type field. This bit is cleared when the DDR4_FSP_CLKCHNG_ACK_ack bit is set.
  [1:0] DDR4_FSP_CLKCHNG_REQ1_REQ_TYPE — Frequency request typeIndicates which DDR4 FSP frequency to which the DDR Controller wants the DDR clock set
0x140C0 CFG0_DDR4_FSP_CLKCHNG_ACK0 — This register is used to acknowledge a DDR0 PLL clock frequency change to the DDR0 Controller.
  [0] DDR4_FSP_CLKCHNG_ACK0_ACK — DDR FSP clock change acknowledgeThis bit should be set once the DDR clock has been successfully changed to the value requested by DDR4_FSP_CLKCHNG_REQ_req_type. Setting this bit will clear the DDR4_FSP_CLKCHNG_REQ_req bit and the associated change request interrupt.
0x140D0 CFG0_DDR4_FSP_CLKCHNG_ACK1 — This register is used to acknowledge a DDR1 PLL clock frequency change to the DDR1 Controller.
  [0] DDR4_FSP_CLKCHNG_ACK1_ACK — DDR FSP clock change acknowledgeThis bit should be set once the DDR clock has been successfully changed to the value requested by DDR4_FSP_CLKCHNG_REQ_req_type. Setting this bit will clear the DDR4_FSP_CLKCHNG_REQ_req bit and the associated change request interrupt.
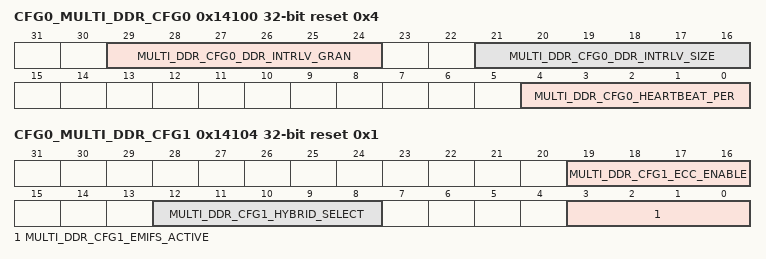
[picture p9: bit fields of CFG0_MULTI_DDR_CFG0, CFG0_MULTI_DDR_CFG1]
0x14100 CFG0_MULTI_DDR_CFG0 reset 0x4 — Configures DDR interleaving
  [29:24] MULTI_DDR_CFG0_DDR_INTRLV_GRAN — Defines the size of each memory stripe for interleaved memory space. Value takes effect when MULTI_DDR_CFG1_ddr_cfg _load field is set as 4'b0110. Field values (Others are reserved): 6'b000000 - 128 B 6'b000001 - 512 B 6'b000010 - 2 KB 6'b000011 - 4 KB 6'b000100 - 16 KB 6'b000101 - 32 KB 6'b000110 - 512 MB 6'b000111 - 1 GB 6'b001000 - 1.5 GB 6'b001001 - 2 GB 6'b001010 - 3 GB 6'b001011 - 4 GB 6'b001100 - 6 GB 6'b001101 - 8 GB 6'b001110 - 16 GB
  [21:16] MULTI_DDR_CFG0_DDR_INTRLV_SIZE — Defines the memory window size for the interleaved region starting at the bottom of the external memory address range. Value takes effect when MULTI_DDR_CFG1_ddr_cfg _load field is set as 4'b0110. Field values (Others are reserved): 6'b000000 - 0 (no interleave) 6'b000001 - 128 MB 6'b000010 - 256 MB 6'b000011 - 512 MB 6'b000100 - 1 GB 6'b000101 - 2 GB 6'b000110 - 3 GB 6'b000111 - 4 GB 6'b001000 - 6 GB 6'b001001 - 8 GB 6'b001010 - 12 GB 6'b001011 - 16 GB 6'b001100 - 32 GB
  [4:0] MULTI_DDR_CFG0_HEARTBEAT_PER — Determines number of cycles of unsuccessful EMIF arbitration to wait before arbitrating for a different EMIF port. Value takes effect when MULTI_DDR_CFG1_ddr_cfg _load field is set as 4'b0110. 0 - Heartbeat is disabled 1-31 - Number of cycles before port switch
0x14104 CFG0_MULTI_DDR_CFG1 reset 0x1 — Configures DDR interleaving
  [19:16] MULTI_DDR_CFG1_ECC_ENABLE — Determines which EMIFs have ECC enabled. Value takes effect when MULTI_DDR_CFG1_ddr_cfg _load field is set as 4'b0110. Field values (Others are reserved): 4'b0000 - ECC disabled on all EMIFs 4'b0001 - ECC enabled on EMIF 0 4'b0010 - ECC enabled on EMIF 1 4'b0011 - ECC enabled on EMIF 0,1
  [12:8] MULTI_DDR_CFG1_HYBRID_SELECT — Determines interleaved EMIF space location. Usage is based on number of EMIFs present. Value takes effect when MULTI_DDR_CFG1_ddr_cfg _load field is set as 4'b0110. Field values (Others are reserved): 4'b00000 - Entire EMIF space is interleaved 4'b00001 - 2 EMIFs - EMIF 0 separated, EMIF 0,1 interleaved 4'b00010 - 2 EMIFs - EMIF 1 separated, EMIF 0,1 interleaved 4'b00100 - 2 EMIFS - reserved 4'b01000 - 2 EMIFS - reserved 4'b10001 - 2 EMIFs - EMIF 0 separated, EMIF 0,1 interleaved 4'b10010 - 2 EMIFs - EMIF 1 separated, EMIF 0,1 interleaved 4'b10100 - 2 EMIFS - reserved 4'b11000 - 2 EMIFS - reserved
  [3:0] MULTI_DDR_CFG1_EMIFS_ACTIVE — Indicates which EMIF (DDR) interfaces are active. Value takes effect when MULTI_DDR_CFG1_ddr_cfg _load field is set as 4'b0110. Field values (Others are reserved): 4'b0000 - Reserved 4'b0001 - EMIF 0 Active 4'b0010 - EMIF 1 Active 4'b0011 - EMIF 0,1 Active
